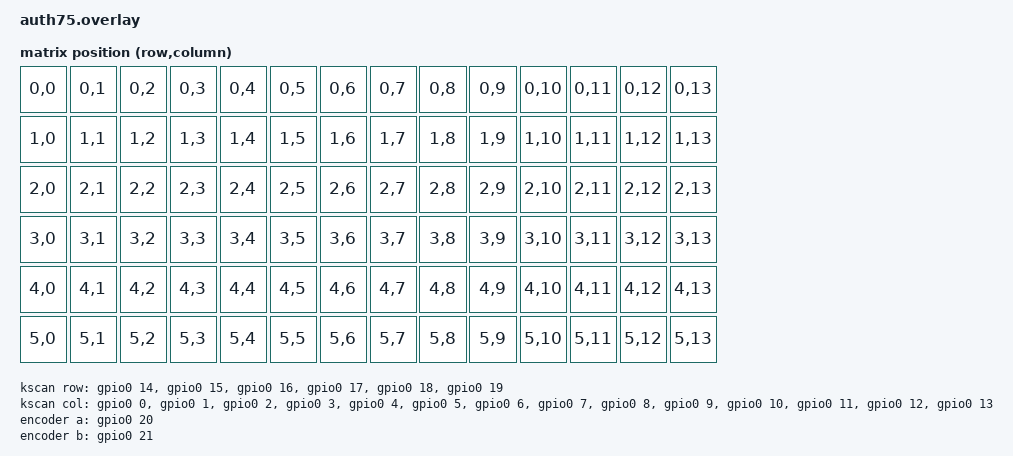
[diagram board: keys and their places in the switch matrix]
// This file was generated from a template. Edit it to match your keyboard.
// See https://zmk.dev/docs/development/hardware-integration/new-shield for more
// instructions.

#include <dt-bindings/zmk/matrix_transform.h>

#include "auth75-layouts.dtsi"

/ {
    chosen {
        zmk,physical-layout = &default_layout;
    };

    kscan: kscan {
        // If the hardware does not use a switch matrix, change this to the
        // appropriate driver and update the properties below to match.
        // See https://zmk.dev/docs/config/kscan for supported key scan drivers.
        compatible = "zmk,kscan-gpio-matrix";
        // Set this to "col2row" or "row2col" to match the hardware. If using
        // "row2col", change the col-gpios to (GPIO_ACTIVE_HIGH | GPIO_PULL_DOWN)
        // and the row-gpios to GPIO_ACTIVE_HIGH.
        diode-direction = "col2row";
        wakeup-source;

        // Replace these comments with the GPIO pins in the matrix.
        // See https://zmk.dev/docs/development/hardware-integration/new-shield#shield-overlays
        col-gpios
            = <&gpio0 0  GPIO_ACTIVE_HIGH>  /* Column 1  */
            , <&gpio0 1  GPIO_ACTIVE_HIGH>  /* Column 2  */
            , <&gpio0 2  GPIO_ACTIVE_HIGH>  /* Column 3  */
            , <&gpio0 3  GPIO_ACTIVE_HIGH>  /* Column 4  */
            , <&gpio0 4  GPIO_ACTIVE_HIGH>  /* Column 5  */
            , <&gpio0 5  GPIO_ACTIVE_HIGH>  /* Column 6  */
            , <&gpio0 6  GPIO_ACTIVE_HIGH>  /* Column 7  */
            , <&gpio0 7  GPIO_ACTIVE_HIGH>  /* Column 8  */
            , <&gpio0 8  GPIO_ACTIVE_HIGH>  /* Column 9  */
            , <&gpio0 9  GPIO_ACTIVE_HIGH>  /* Column 10 */
            , <&gpio0 10 GPIO_ACTIVE_HIGH>  /* Column 11 */
            , <&gpio0 11 GPIO_ACTIVE_HIGH>  /* Column 12 */
            , <&gpio0 12 GPIO_ACTIVE_HIGH>  /* Column 13 */
            , <&gpio0 13 GPIO_ACTIVE_HIGH>  /* Column 14 */
            ;

        row-gpios
            = <&gpio0 14 (GPIO_ACTIVE_HIGH | GPIO_PULL_DOWN)>  /* Row 1 */
            , <&gpio0 15 (GPIO_ACTIVE_HIGH | GPIO_PULL_DOWN)>  /* Row 2 */
            , <&gpio0 16 (GPIO_ACTIVE_HIGH | GPIO_PULL_DOWN)>  /* Row 3 */
            , <&gpio0 17 (GPIO_ACTIVE_HIGH | GPIO_PULL_DOWN)>  /* Row 4 */
            , <&gpio0 18 (GPIO_ACTIVE_HIGH | GPIO_PULL_DOWN)>  /* Row 5 */
            , <&gpio0 19 (GPIO_ACTIVE_HIGH | GPIO_PULL_DOWN)>  /* Row 6 */
            ;
    };

    default_transform: default_transform {
        compatible = "zmk,matrix-transform";
        columns = <14>;
        rows = <6>;

        map = <
            RC(0,0)  RC(0,1)  RC(0,2)  RC(0,3)  RC(0,4)  RC(0,5)  RC(0,6)  RC(0,7)  RC(0,8)  RC(0,9)  RC(0,10) RC(0,11) RC(0,12) RC(0,13)
            RC(1,0)  RC(1,1)  RC(1,2)  RC(1,3)  RC(1,4)  RC(1,5)  RC(1,6)  RC(1,7)  RC(1,8)  RC(1,9)  RC(1,10) RC(1,11) RC(1,12) RC(1,13)
            RC(2,0)  RC(2,1)  RC(2,2)  RC(2,3)  RC(2,4)  RC(2,5)  RC(2,6)  RC(2,7)  RC(2,8)  RC(2,9)  RC(2,10) RC(2,11) RC(2,12) RC(2,13)
            RC(3,0)  RC(3,1)  RC(3,2)  RC(3,3)  RC(3,4)  RC(3,5)  RC(3,6)  RC(3,7)  RC(3,8)  RC(3,9)  RC(3,10) RC(3,11) RC(3,12) RC(3,13)
            RC(4,0)  RC(4,1)  RC(4,2)  RC(4,3)  RC(4,4)  RC(4,5)  RC(4,6)  RC(4,7)  RC(4,8)  RC(4,9)  RC(4,10) RC(4,11) RC(4,12) RC(4,13)
            RC(5,0)  RC(5,1)  RC(5,2)  RC(5,3)  RC(5,4)  RC(5,5)  RC(5,6)  RC(5,7)  RC(5,8)  RC(5,9)  RC(5,10) RC(5,11) RC(5,12) RC(5,13)
        >;
    };

    encoder: encoder {
        compatible = "alps,ec11";
        a-gpios = <&gpio0 20 (GPIO_ACTIVE_HIGH | GPIO_PULL_UP)>;
        b-gpios = <&gpio0 21 (GPIO_ACTIVE_HIGH | GPIO_PULL_UP)>;
        steps = <80>;
        status = "okay";
    };

    sensors: sensors {
        compatible = "zmk,keymap-sensors";
        sensors = <&encoder>;
        triggers-per-rotation = <20>;
    };
};
